# STM32WB35_CM4 register map
File version: 1.3-IAR
CPU: CM4 r0p1, little endian, MPU, FPU, 4 interrupt priority bits
Registers are 32-bit, read-write, reset 0x0 unless marked. A register's access mark holds for its fields unless they carry their own. Offsets are from the block's base; [hi:lo] are bit positions.

## CRC — Cyclic redundancy check calculation unit
Base 0x40023000
0x00 DR reset 0xFFFFFFFF — Data register
  [31:0] DR — Data register bits
0x04 IDR — Independent data register
  [31:0] IDR — General-purpose 32-bit data register bits
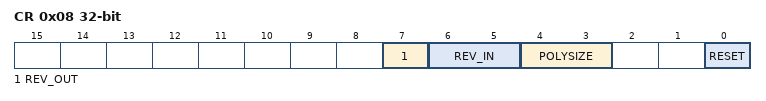
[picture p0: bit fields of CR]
0x08 CR — Control register
  [7] REV_OUT — Reverse output data
  [6:5] REV_IN — Reverse input data
  [4:3] POLYSIZE — Polynomial size
  [0] RESET — RESET bit
0x10 INIT reset 0xFFFFFFFF — Initial CRC value
  [31:0] CRC_INIT — Programmable initial CRC value
0x14 POL reset 0x4C11DB7 — polynomial
  [31:0] POL — Programmable polynomial

## IWDG — Independent watchdog
Base 0x40003000
0x00 KR wo — Key register
  [15:0] KEY — Key value (write only, read 0x0000)
0x04 PR — Prescaler register
  [2:0] PR — Prescaler divider
0x08 RLR reset 0xFFF — Reload register
  [11:0] RL — Watchdog counter reload value
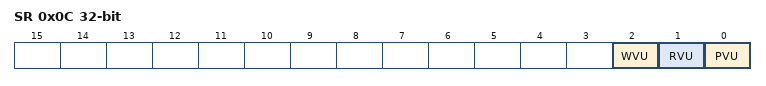
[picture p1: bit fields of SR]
0x0C SR ro — Status register
  [2] WVU — Watchdog counter window value update
  [1] RVU — Watchdog counter reload value update
  [0] PVU — Watchdog prescaler value update
0x10 WINR reset 0xFFF — Window register
  [11:0] WIN — Watchdog counter window value

## WWDG — System window watchdog
Base 0x40002C00
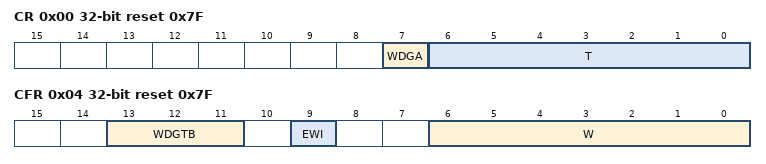
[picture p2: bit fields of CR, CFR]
0x00 CR reset 0x7F — Control register
  [7] WDGA — Activation bit
  [6:0] T — 7-bit counter (MSB to LSB)
0x04 CFR reset 0x7F — Configuration register
  [13:11] WDGTB — Timer base
  [9] EWI — Early wakeup interrupt
  [6:0] W — 7-bit window value
0x08 SR — Status register
  [0] EWIF — Early wakeup interrupt flag

## COMP — Comparator instance 1
Base 0x40010200
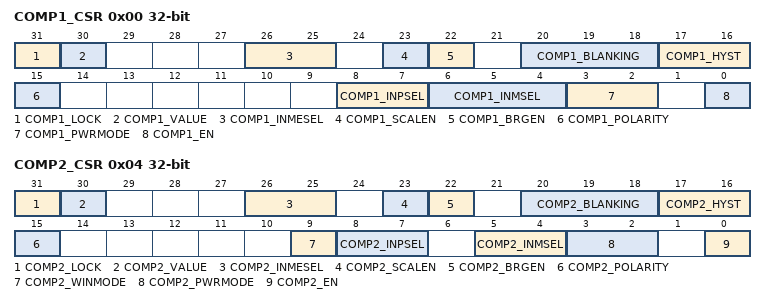
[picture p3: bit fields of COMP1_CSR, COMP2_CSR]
0x00 COMP1_CSR access per field — Comparator control and status register
  [31] COMP1_LOCK rw — Comparator lock
  [30] COMP1_VALUE ro — Comparator output level
  [26:25] COMP1_INMESEL rw — Comparator input minus extended selection
  [23] COMP1_SCALEN rw — Comparator scaler bridge enable
  [22] COMP1_BRGEN rw — Comparator voltage scaler enable
  [20:18] COMP1_BLANKING rw — Comparator blanking source
  [17:16] COMP1_HYST rw — Comparator hysteresis
  [15] COMP1_POLARITY rw — Comparator output polarity
  [8:7] COMP1_INPSEL rw — Comparator input plus selection
  [6:4] COMP1_INMSEL rw — Comparator input minus selection
  [3:2] COMP1_PWRMODE rw — Comparator power mode
  [0] COMP1_EN rw — Comparator enable
0x04 COMP2_CSR access per field — Comparator 2 control and status register
  [31] COMP2_LOCK rw — CSR register lock bit
  [30] COMP2_VALUE ro — Comparator 2 output status bit
  [26:25] COMP2_INMESEL rw — comparator 2 input minus extended selection bits.
  [23] COMP2_SCALEN rw — Voltage scaler enable bit
  [22] COMP2_BRGEN rw — Scaler bridge enable
  [20:18] COMP2_BLANKING rw — Comparator 2 blanking source selection bits
  [17:16] COMP2_HYST rw — Comparator 2 hysteresis selection bits
  [15] COMP2_POLARITY rw — Comparator 2 polarity selection bit
  [9] COMP2_WINMODE rw — Windows mode selection bit
  [8:7] COMP2_INPSEL rw — Comparator 1 input plus selection bit
  [5:4] COMP2_INMSEL rw — Comparator 2 input minus selection bits
  [3:2] COMP2_PWRMODE rw — Power Mode of the comparator 2
  [0] COMP2_EN rw — Comparator 2 enable bit

## QUADSPI — QuadSPI interface
Base 0xA0001000
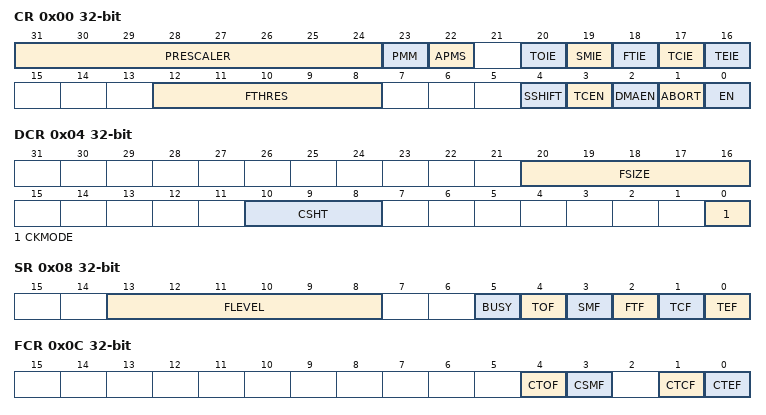
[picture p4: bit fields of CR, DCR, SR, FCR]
0x00 CR — control register
  [31:24] PRESCALER — Clock prescaler
  [23] PMM — Polling match mode
  [22] APMS — Automatic poll mode stop
  [20] TOIE — TimeOut interrupt enable
  [19] SMIE — Status match interrupt enable
  [18] FTIE — FIFO threshold interrupt enable
  [17] TCIE — Transfer complete interrupt enable
  [16] TEIE — Transfer error interrupt enable
  [12:8] FTHRES — FIFO threshold level
  [4] SSHIFT — Sample shift
  [3] TCEN — Timeout counter enable
  [2] DMAEN — DMA enable
  [1] ABORT — Abort request
  [0] EN — Enable
0x04 DCR — device configuration register
  [20:16] FSIZE — FLASH memory size
  [10:8] CSHT — Chip select high time
  [0] CKMODE — Mode 0 / mode 3
0x08 SR ro — status register
  [13:8] FLEVEL — FIFO level
  [5] BUSY
  [4] TOF — Timeout flag
  [3] SMF — Status match flag
  [2] FTF — FIFO threshold flag
  [1] TCF — Transfer complete flag
  [0] TEF — Transfer error flag
0x0C FCR — flag clear register
  [4] CTOF — Clear timeout flag
  [3] CSMF — Clear status match flag
  [1] CTCF — Clear transfer complete flag
  [0] CTEF — Clear transfer error flag
0x10 DLR — data length register
  [31:0] DL — Data length
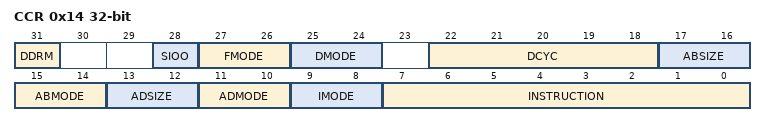
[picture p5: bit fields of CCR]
0x14 CCR — communication configuration register
  [31] DDRM — Double data rate mode
  [28] SIOO — Send instruction only once mode
  [27:26] FMODE — Functional mode
  [25:24] DMODE — Data mode
  [22:18] DCYC — Number of dummy cycles
  [17:16] ABSIZE — Alternate bytes size
  [15:14] ABMODE — Alternate bytes mode
  [13:12] ADSIZE — Address size
  [11:10] ADMODE — Address mode
  [9:8] IMODE — Instruction mode
  [7:0] INSTRUCTION
0x18 AR — address register
  [31:0] ADDRESS
0x1C ABR
  [31:0] ALTERNATE
0x20 DR — data register
  [31:0] DATA
0x24 PSMKR — polling status mask register
  [31:0] MASK — Status mask
0x28 PSMAR — polling status match register
  [31:0] MATCH — Status match
0x2C PIR — polling interval register
  [15:0] INTERVAL — Polling interval
0x30 LPTR — low-power timeout register
  [15:0] TIMEOUT — Timeout period
